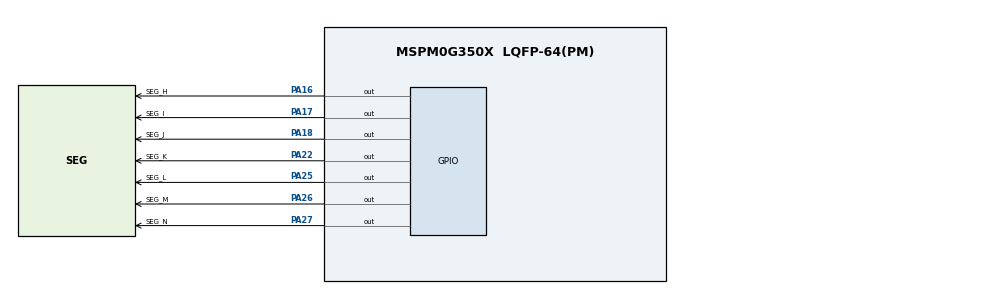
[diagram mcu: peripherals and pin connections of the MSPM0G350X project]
/**
 * @cliArgs --device "MSPM0G350X" --package "LQFP-64(PM)" --part "Default" --product "mspm0_sdk@1.20.00.06"
 * @versions {"tool":"1.18.0+3266"}
 */

/**
 * Import the modules used in this configuration.
 */
const GPIO   = scripting.addModule("/ti/driverlib/GPIO", {}, false);
const GPIO1  = GPIO.addInstance();
const GPIO2  = GPIO.addInstance();
const SYSCTL = scripting.addModule("/ti/driverlib/SYSCTL");

/**
 * Write custom configuration values to the imported modules.
 */
GPIO1.$name                              = "SEGMENT_DISPLAY_1";
GPIO1.port                               = "PORTA";
GPIO1.associatedPins.create(7);
GPIO1.associatedPins[0].$name            = "SEG_A";
GPIO1.associatedPins[0].assignedPin      = "8";
GPIO1.associatedPins[0].internalResistor = "PULL_DOWN";
GPIO1.associatedPins[1].$name            = "SEG_B";
GPIO1.associatedPins[1].assignedPin      = "9";
GPIO1.associatedPins[1].internalResistor = "PULL_DOWN";
GPIO1.associatedPins[2].$name            = "SEG_C";
GPIO1.associatedPins[2].assignedPin      = "10";
GPIO1.associatedPins[2].internalResistor = "PULL_DOWN";
GPIO1.associatedPins[3].$name            = "SEG_D";
GPIO1.associatedPins[3].assignedPin      = "11";
GPIO1.associatedPins[3].internalResistor = "PULL_DOWN";
GPIO1.associatedPins[4].$name            = "SEG_E";
GPIO1.associatedPins[4].assignedPin      = "12";
GPIO1.associatedPins[4].internalResistor = "PULL_DOWN";
GPIO1.associatedPins[5].$name            = "SEG_F";
GPIO1.associatedPins[5].assignedPin      = "13";
GPIO1.associatedPins[5].internalResistor = "PULL_DOWN";
GPIO1.associatedPins[6].$name            = "SEG_G";
GPIO1.associatedPins[6].assignedPin      = "15";
GPIO1.associatedPins[6].internalResistor = "PULL_DOWN";

const Board = scripting.addModule("/ti/driverlib/Board", {}, false);

GPIO2.$name                              = "SEGMENT_DISPLAY_2";
GPIO2.port                               = "PORTA";
GPIO2.associatedPins.create(7);
GPIO2.associatedPins[0].$name            = "SEG_H";
GPIO2.associatedPins[0].assignedPin      = "16";
GPIO2.associatedPins[0].internalResistor = "PULL_DOWN";
GPIO2.associatedPins[0].pin.$assign      = "PA16";
GPIO2.associatedPins[1].$name            = "SEG_I";
GPIO2.associatedPins[1].assignedPin      = "17";
GPIO2.associatedPins[1].internalResistor = "PULL_DOWN";
GPIO2.associatedPins[1].pin.$assign      = "PA17";
GPIO2.associatedPins[2].$name            = "SEG_J";
GPIO2.associatedPins[2].assignedPin      = "18";
GPIO2.associatedPins[2].internalResistor = "PULL_DOWN";
GPIO2.associatedPins[2].pin.$assign      = "PA18";
GPIO2.associatedPins[3].$name            = "SEG_K";
GPIO2.associatedPins[3].assignedPin      = "22";
GPIO2.associatedPins[3].internalResistor = "PULL_DOWN";
GPIO2.associatedPins[3].pin.$assign      = "PA22";
GPIO2.associatedPins[4].$name            = "SEG_L";
GPIO2.associatedPins[4].assignedPin      = "25";
GPIO2.associatedPins[4].internalResistor = "PULL_DOWN";
GPIO2.associatedPins[4].pin.$assign      = "PA25";
GPIO2.associatedPins[5].$name            = "SEG_M";
GPIO2.associatedPins[5].assignedPin      = "26";
GPIO2.associatedPins[5].internalResistor = "PULL_DOWN";
GPIO2.associatedPins[5].pin.$assign      = "PA26";
GPIO2.associatedPins[6].$name            = "SEG_N";
GPIO2.associatedPins[6].assignedPin      = "27";
GPIO2.associatedPins[6].internalResistor = "PULL_DOWN";
GPIO2.associatedPins[6].pin.$assign      = "PA27";

SYSCTL.MFCLKEn = true;

/**
 * Pinmux solution for unlocked pins/peripherals. This ensures that minor changes to the automatic solver in a future
 * version of the tool will not impact the pinmux you originally saw.  These lines can be completely deleted in order to
 * re-solve from scratch.
 */
GPIO1.associatedPins[0].pin.$suggestSolution = "PA8";
GPIO1.associatedPins[1].pin.$suggestSolution = "PA9";
GPIO1.associatedPins[2].pin.$suggestSolution = "PA10";
GPIO1.associatedPins[3].pin.$suggestSolution = "PA11";
GPIO1.associatedPins[4].pin.$suggestSolution = "PA12";
GPIO1.associatedPins[5].pin.$suggestSolution = "PA13";
GPIO1.associatedPins[6].pin.$suggestSolution = "PA15";
Board.peripheral.$suggestSolution            = "DEBUGSS";
Board.peripheral.swclkPin.$suggestSolution   = "PA20";
Board.peripheral.swdioPin.$suggestSolution   = "PA19";
SYSCTL.peripheral.$suggestSolution           = "SYSCTL";
